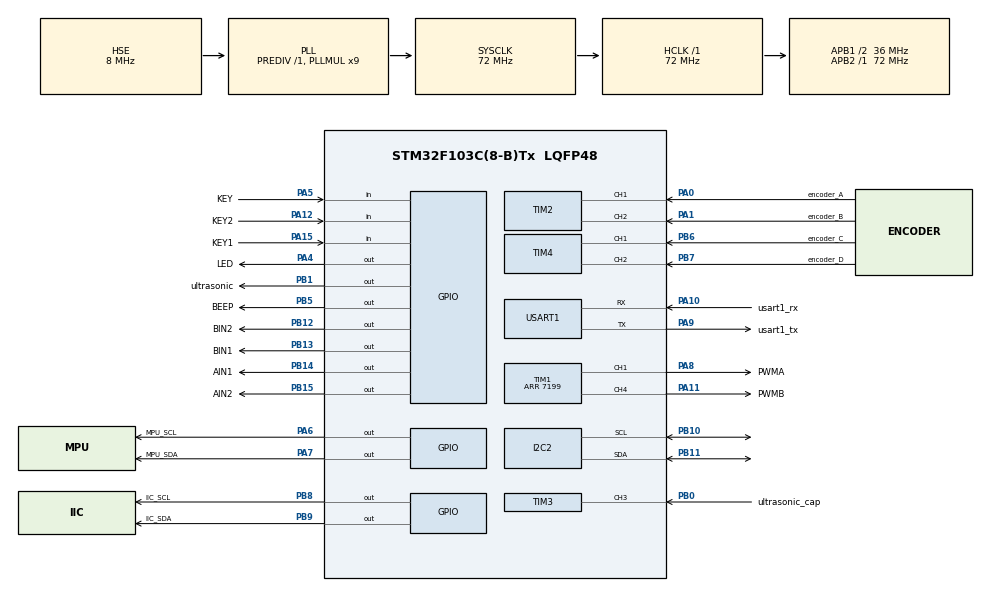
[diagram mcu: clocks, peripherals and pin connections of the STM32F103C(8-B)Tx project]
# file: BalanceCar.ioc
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Mcu.Family=STM32F1
Mcu.Name=STM32F103C(8-B)Tx
Mcu.Package=LQFP48
NVIC.PriorityGroup=NVIC_PRIORITYGROUP_2
NVIC.TIM3_IRQn=true\:1\:1\:true\:false\:true\:true\:true\:true
PA0-WKUP.GPIO_Label=encoder_A
PA0-WKUP.Signal=S_TIM2_CH1_ETR
PA1.GPIO_Label=encoder_B
PA1.Signal=S_TIM2_CH2
PA10.GPIO_Label=usart1_rx
PA10.Mode=Asynchronous
PA10.Signal=USART1_RX
PA11.GPIO_Label=PWMB
PA11.Signal=S_TIM1_CH4
PA13.Mode=Serial_Wire
PA13.Signal=SYS_JTMS-SWDIO
PA14.Mode=Serial_Wire
PA14.Signal=SYS_JTCK-SWCLK
PA15.GPIO_Label=KEY1
PA15.GPIO_PuPd=GPIO_PULLUP
PA15.Signal=GPIO_Input
PA6.GPIO_Label=MPU_SCL
PA6.GPIO_Speed=GPIO_SPEED_FREQ_HIGH
PA6.PinState=GPIO_PIN_SET
PA6.Signal=GPIO_Output
PA7.GPIO_Label=MPU_SDA
PA7.GPIO_Speed=GPIO_SPEED_FREQ_HIGH
PA7.PinState=GPIO_PIN_SET
PA7.Signal=GPIO_Output
PA12.GPIO_Label=KEY2
PA12.GPIO_PuPd=GPIO_PULLUP
PA12.Signal=GPIO_Input
PA4.GPIO_Label=LED
PA4.GPIO_ModeDefaultOutputPP=GPIO_MODE_OUTPUT_PP
PA4.GPIO_PuPd=GPIO_NOPULL
PA4.GPIO_Speed=GPIO_SPEED_FREQ_HIGH
PA4.PinState=GPIO_PIN_SET
PA4.Signal=GPIO_Output
PA5.GPIO_Label=KEY
PA5.GPIO_PuPd=GPIO_PULLUP
PA5.Signal=GPIO_Input
PA8.GPIO_Label=PWMA
PA8.Signal=S_TIM1_CH1
PA9.GPIO_Label=usart1_tx
PA9.Mode=Asynchronous
PA9.Signal=USART1_TX
PB0.GPIO_Label=ultrasonic_cap
PB0.Signal=S_TIM3_CH3
PB1.GPIO_Label=ultrasonic
PB1.GPIO_Speed=GPIO_SPEED_FREQ_HIGH
PB1.Signal=GPIO_Output
PB10.Mode=I2C
PB10.Signal=I2C2_SCL
PB11.Mode=I2C
PB11.Signal=I2C2_SDA
PB12.GPIO_Label=BIN2
PB12.GPIO_Speed=GPIO_SPEED_FREQ_HIGH
PB12.Signal=GPIO_Output
PB13.GPIO_Label=BIN1
PB13.GPIO_Speed=GPIO_SPEED_FREQ_HIGH
PB13.Signal=GPIO_Output
PB14.GPIO_Label=AIN1
PB14.GPIO_Speed=GPIO_SPEED_FREQ_HIGH
PB14.Signal=GPIO_Output
PB15.GPIO_Label=AIN2
PB15.GPIO_Speed=GPIO_SPEED_FREQ_HIGH
PB15.Signal=GPIO_Output
PB5.GPIO_Label=BEEP
PB5.GPIO_Speed=GPIO_SPEED_FREQ_MEDIUM
PB5.Signal=GPIO_Output
PB6.GPIO_Label=encoder_C
PB6.Signal=S_TIM4_CH1
PB7.GPIO_Label=encoder_D
PB7.Signal=S_TIM4_CH2
PB8.GPIO_Label=IIC_SCL
PB8.GPIO_Speed=GPIO_SPEED_FREQ_HIGH
PB8.PinState=GPIO_PIN_SET
PB8.Signal=GPIO_Output
PB9.GPIO_Label=IIC_SDA
PB9.GPIO_Speed=GPIO_SPEED_FREQ_HIGH
PB9.PinState=GPIO_PIN_SET
PB9.Signal=GPIO_Output
PD0-OSC_IN.Mode=HSE-External-Oscillator
PD0-OSC_IN.Signal=RCC_OSC_IN
PD1-OSC_OUT.Mode=HSE-External-Oscillator
PD1-OSC_OUT.Signal=RCC_OSC_OUT
ProjectManager.HeapSize=0x200
ProjectManager.StackSize=0x400
ProjectManager.TargetToolchain=MDK-ARM V5.32
RCC.ADCPresc=RCC_ADCPCLK2_DIV6
RCC.AHBFreq_Value=72000000
RCC.APB1CLKDivider=RCC_HCLK_DIV2
RCC.APB1Freq_Value=36000000
RCC.APB1TimFreq_Value=72000000
RCC.APB2Freq_Value=72000000
RCC.APB2TimFreq_Value=72000000
RCC.HCLKFreq_Value=72000000
RCC.PLLMUL=RCC_PLL_MUL9
RCC.PLLSourceVirtual=RCC_PLLSOURCE_HSE
RCC.SYSCLKFreq_VALUE=72000000
RCC.SYSCLKSource=RCC_SYSCLKSOURCE_PLLCLK
RCC.TimSys_Div=SYSTICK_CLKSOURCE_HCLK_DIV8
RCC.USBFreq_Value=72000000
SH.S_TIM1_CH1.0=TIM1_CH1,PWM Generation1 CH1
SH.S_TIM1_CH4.0=TIM1_CH4,PWM Generation4 CH4
SH.S_TIM2_CH1_ETR.0=TIM2_CH1,Encoder_Interface
SH.S_TIM2_CH2.0=TIM2_CH2,Encoder_Interface
SH.S_TIM3_CH3.0=TIM3_CH3,Input_Capture3_from_TI3
SH.S_TIM4_CH1.0=TIM4_CH1,Encoder_Interface
SH.S_TIM4_CH2.0=TIM4_CH2,Encoder_Interface
TIM1.AutoReloadPreload=TIM_AUTORELOAD_PRELOAD_ENABLE
TIM1.Channel-PWM\ Generation1\ CH1=TIM_CHANNEL_1
TIM1.Channel-PWM\ Generation4\ CH4=TIM_CHANNEL_4
TIM1.Period=7199
TIM2.EncoderMode=TIM_ENCODERMODE_TI12
TIM2.IC1Filter=10
TIM2.IC2Filter=10
TIM3.AutoReloadPreload=TIM_AUTORELOAD_PRELOAD_ENABLE
TIM3.Channel-Input_Capture3_from_TI3=TIM_CHANNEL_3
TIM3.Period=9999
TIM3.Prescaler=72-1
TIM4.EncoderMode=TIM_ENCODERMODE_TI12
TIM4.IC1Filter=10
TIM4.IC2Filter=10
USART1.VirtualMode=VM_ASYNC
VP_TIM1_VS_ClockSourceINT.Mode=Internal
VP_TIM3_VS_ClockSourceINT.Mode=Internal
board=custom

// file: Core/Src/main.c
/* USER CODE BEGIN Header */
/**
 ******************************************************************************
 * @file           : main.c
 * @brief          : Main program body
 ******************************************************************************
 * @attention
 *
 * <h2><center>&copy; Copyright (c) 2021 STMicroelectronics.
 * All rights reserved.</center></h2>
 *
 * This software component is licensed by ST under BSD 3-Clause license,
 * the "License"; You may not use this file except in compliance with the
 * License. You may obtain a copy of the License at:
 *                        opensource.org/licenses/BSD-3-Clause
 *
 ******************************************************************************
 */
/* USER CODE END Header */
#include "main.h"
#include "i2c.h"
#include "tim.h"
#include "usart.h"
#include "gpio.h"

/* USER CODE BEGIN Includes */
#include "sys.h"
#include "car_config.h"
#include "car_core.h"
/* USER CODE END Includes */

/* USER CODE BEGIN PTD */
/* tim.c 的 Read_Distane() 还在引用它, 保留定义免得链接报错(本工程不再使用) */
BalanceCarTypeDef BalanceCar;
/* USER CODE END PTD */

void SystemClock_Config(void);

int main(void)
{

  /* MCU Configuration--------------------------------------------------------*/

  /* Reset of all peripherals, Initializes the Flash interface and the Systick. */
  HAL_Init();

  /* Configure the system clock */
  SystemClock_Config();

  /* Initialize all configured peripherals */
  MX_GPIO_Init();
  MX_USART1_UART_Init();
  MX_TIM3_Init();
  MX_TIM1_Init();
  MX_TIM2_Init();
  MX_TIM4_Init();
  MX_I2C2_Init();
  /* USER CODE BEGIN 2 */
    JTAG_Set(JTAG_SWD_DISABLE);         // 关闭JTAG接口
    JTAG_Set(SWD_ENABLE);               // 打开SWD接口 可以利用主板的SWD接口调试
    delay_init();                       // 延迟函数初始化

    /* 循迹小车: 所有模块在 Car_Init() 里按 car_config.h 的开关初始化
       10ms 定时任务走 TIM3 -> Car_10msTask() (见 car_core.c 末尾) */
    Car_Init();

  /* USER CODE END 2 */

  /* Infinite loop */
  /* USER CODE BEGIN WHILE */
    while (1)
    {
        Car_Poll();                     // 灰度/转向/按键/OLED/串口打印
    /* USER CODE END WHILE */

    }
}

void SystemClock_Config(void)
{
  RCC_OscInitTypeDef RCC_OscInitStruct = {0};
  RCC_ClkInitTypeDef RCC_ClkInitStruct = {0};

  /** Initializes the RCC Oscillators according to the specified parameters
  * in the RCC_OscInitTypeDef structure.
  */
  RCC_OscInitStruct.OscillatorType = RCC_OSCILLATORTYPE_HSE;
  RCC_OscInitStruct.HSEState = RCC_HSE_ON;
  RCC_OscInitStruct.HSEPredivValue = RCC_HSE_PREDIV_DIV1;
  RCC_OscInitStruct.HSIState = RCC_HSI_ON;
  RCC_OscInitStruct.PLL.PLLState = RCC_PLL_ON;
  RCC_OscInitStruct.PLL.PLLSource = RCC_PLLSOURCE_HSE;
  RCC_OscInitStruct.PLL.PLLMUL = RCC_PLL_MUL9;
  if (HAL_RCC_OscConfig(&RCC_OscInitStruct) != HAL_OK)
  {
    Error_Handler();
  }

  /** Initializes the CPU, AHB and APB buses clocks
  */
  RCC_ClkInitStruct.ClockType = RCC_CLOCKTYPE_HCLK|RCC_CLOCKTYPE_SYSCLK
                              |RCC_CLOCKTYPE_PCLK1|RCC_CLOCKTYPE_PCLK2;
  RCC_ClkInitStruct.SYSCLKSource = RCC_SYSCLKSOURCE_PLLCLK;
  RCC_ClkInitStruct.AHBCLKDivider = RCC_SYSCLK_DIV1;
  RCC_ClkInitStruct.APB1CLKDivider = RCC_HCLK_DIV2;
  RCC_ClkInitStruct.APB2CLKDivider = RCC_HCLK_DIV1;

  if (HAL_RCC_ClockConfig(&RCC_ClkInitStruct, FLASH_LATENCY_2) != HAL_OK)
  {
    Error_Handler();
  }
}

void Error_Handler(void)
{
    __disable_irq();
    while (1)
    {
    }
}
